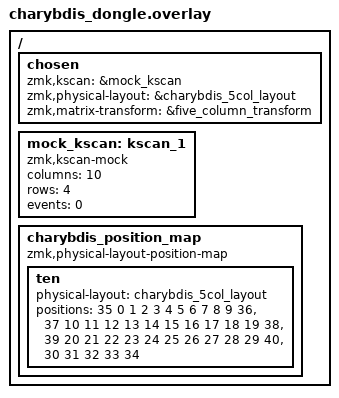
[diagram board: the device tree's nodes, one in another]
#include "charybdis.dtsi"

/ {
    chosen {
        zmk,kscan = &mock_kscan;
        zmk,physical-layout = &charybdis_5col_layout;
        zmk,matrix-transform = &five_column_transform;
    };

    mock_kscan: kscan_1 {
        compatible = "zmk,kscan-mock";
        columns = <10>;
        rows = <4>;
        events = <0>;
    };

    charybdis_position_map {
        compatible = "zmk,physical-layout-position-map";

        ten {
            physical-layout = <&charybdis_5col_layout>;
            positions
                = <35  0  1  2  3  4  5  6  7  8  9 36>
                , <37 10 11 12 13 14 15 16 17 18 19 38>
                , <39 20 21 22 23 24 25 26 27 28 29 40>
                , <         30 31 32 33 34            >
                ;
        };
    };
};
